# STM32F411VET6 register map
File version: 1.0
Registers are 32-bit, access not given, reset 0x0 unless marked. A register's access mark holds for its fields unless they carry their own. Offsets are from the block's base; [hi:lo] are bit positions; {n}, {i} and the like mark numbered series.

## FLASH
Base 0x40023C00
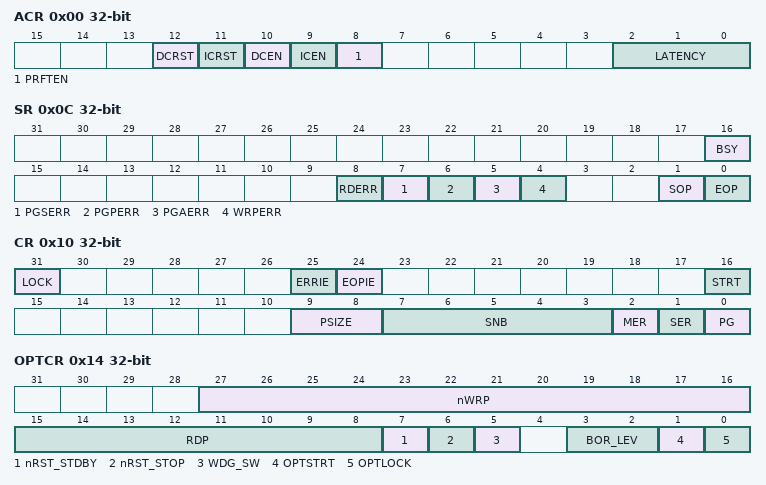
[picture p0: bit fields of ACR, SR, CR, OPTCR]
0x00 ACR
  [12] DCRST, [11] ICRST, [10] DCEN, [9] ICEN, [8] PRFTEN, [2:0] LATENCY
0x04 KEYR
0x08 OPTKEYR
0x0C SR
  [16] BSY, [8] RDERR, [7] PGSERR, [6] PGPERR, [5] PGAERR, [4] WRPERR, [1] SOP, [0] EOP
0x10 CR
  [31] LOCK, [25] ERRIE, [24] EOPIE, [16] STRT, [9:8] PSIZE, [7:3] SNB, [2] MER, [1] SER, [0] PG
0x14 OPTCR
  [27:16] nWRP, [15:8] RDP, [7] nRST_STDBY, [6] nRST_STOP, [5] WDG_SW, [3:2] BOR_LEV, [1] OPTSTRT, [0] OPTLOCK
0x18 OPTCR1
  [27:16] nWRP

## DMA1
Base 0x40026000
Same registers: DMA2 0x40026400
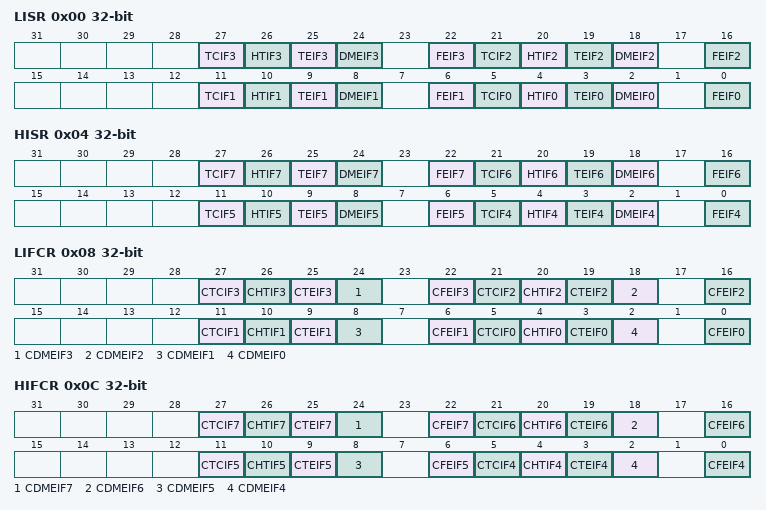
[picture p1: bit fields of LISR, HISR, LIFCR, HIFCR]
0x00 LISR
  [27] TCIF3, [26] HTIF3, [25] TEIF3, [24] DMEIF3, [22] FEIF3, [21] TCIF2, [20] HTIF2, [19] TEIF2, [18] DMEIF2, [16] FEIF2, [11] TCIF1, [10] HTIF1, [9] TEIF1, [8] DMEIF1, [6] FEIF1, [5] TCIF0, [4] HTIF0, [3] TEIF0, [2] DMEIF0, [0] FEIF0
0x04 HISR
  [27] TCIF7, [26] HTIF7, [25] TEIF7, [24] DMEIF7, [22] FEIF7, [21] TCIF6, [20] HTIF6, [19] TEIF6, [18] DMEIF6, [16] FEIF6, [11] TCIF5, [10] HTIF5, [9] TEIF5, [8] DMEIF5, [6] FEIF5, [5] TCIF4, [4] HTIF4, [3] TEIF4, [2] DMEIF4, [0] FEIF4
0x08 LIFCR
  [27] CTCIF3, [26] CHTIF3, [25] CTEIF3, [24] CDMEIF3, [22] CFEIF3, [21] CTCIF2, [20] CHTIF2, [19] CTEIF2, [18] CDMEIF2, [16] CFEIF2, [11] CTCIF1, [10] CHTIF1, [9] CTEIF1, [8] CDMEIF1, [6] CFEIF1, [5] CTCIF0, [4] CHTIF0, [3] CTEIF0, [2] CDMEIF0, [0] CFEIF0
0x0C HIFCR
  [27] CTCIF7, [26] CHTIF7, [25] CTEIF7, [24] CDMEIF7, [22] CFEIF7, [21] CTCIF6, [20] CHTIF6, [19] CTEIF6, [18] CDMEIF6, [16] CFEIF6, [11] CTCIF5, [10] CHTIF5, [9] CTEIF5, [8] CDMEIF5, [6] CFEIF5, [5] CTCIF4, [4] CHTIF4, [3] CTEIF4, [2] CDMEIF4, [0] CFEIF4
{0x10+0x18*i} CR{i} (i=0..7)
{0x14+0x18*i} NDTR{i} (i=0..7)
{0x18+0x18*i} PAR{i} (i=0..7)
{0x1C+0x18*i} M0AR{i} (i=0..7)
{0x20+0x18*i} M1AR{i} (i=0..7)
{0x24+0x18*i} FCR{i} (i=0..7)

## USB_OTG_FS
Base 0x50000000
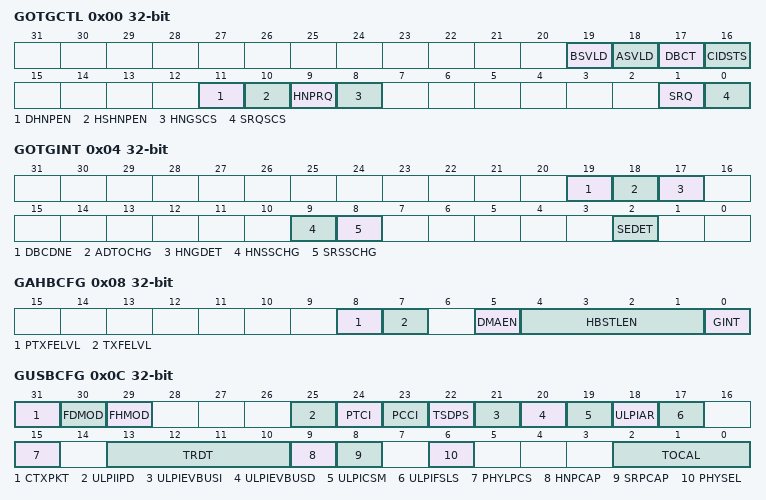
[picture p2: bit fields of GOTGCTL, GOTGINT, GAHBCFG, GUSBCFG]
0x00 GOTGCTL
  [19] BSVLD, [18] ASVLD, [17] DBCT, [16] CIDSTS, [11] DHNPEN, [10] HSHNPEN, [9] HNPRQ, [8] HNGSCS, [1] SRQ, [0] SRQSCS
0x04 GOTGINT
  [19] DBCDNE, [18] ADTOCHG, [17] HNGDET, [9] HNSSCHG, [8] SRSSCHG, [2] SEDET
0x08 GAHBCFG
  [8] PTXFELVL, [7] TXFELVL, [5] DMAEN, [4:1] HBSTLEN, [0] GINT
0x0C GUSBCFG
  [31] CTXPKT, [30] FDMOD, [29] FHMOD, [25] ULPIIPD, [24] PTCI, [23] PCCI, [22] TSDPS, [21] ULPIEVBUSI, [20] ULPIEVBUSD, [19] ULPICSM, [18] ULPIAR, [17] ULPIFSLS, [15] PHYLPCS, [13:10] TRDT, [9] HNPCAP, [8] SRPCAP, [6] PHYSEL, [2:0] TOCAL
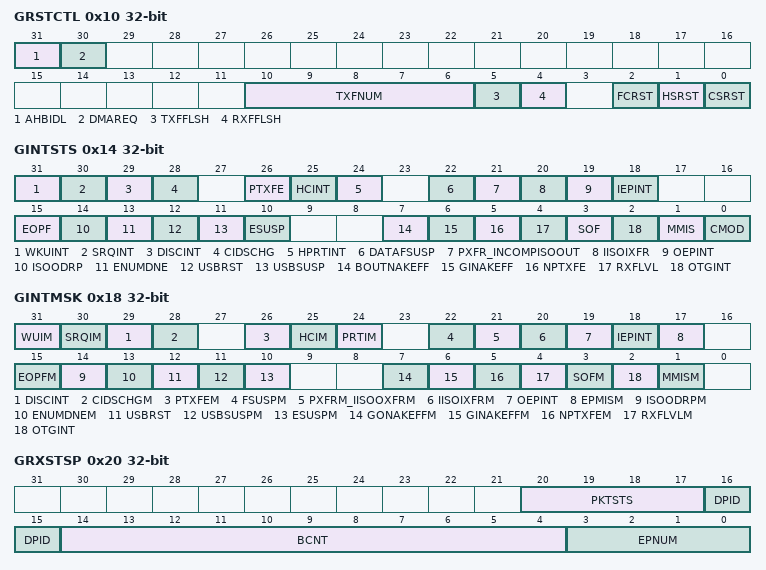
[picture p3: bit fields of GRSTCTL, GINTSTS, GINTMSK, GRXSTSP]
0x10 GRSTCTL
  [31] AHBIDL, [30] DMAREQ, [10:6] TXFNUM, [5] TXFFLSH, [4] RXFFLSH, [2] FCRST, [1] HSRST, [0] CSRST
0x14 GINTSTS
  [31] WKUINT, [30] SRQINT, [29] DISCINT, [28] CIDSCHG, [26] PTXFE, [25] HCINT, [24] HPRTINT, [22] DATAFSUSP, [21] PXFR_INCOMPISOOUT, [20] IISOIXFR, [19] OEPINT, [18] IEPINT, [15] EOPF, [14] ISOODRP, [13] ENUMDNE, [12] USBRST, [11] USBSUSP, [10] ESUSP, [7] BOUTNAKEFF, [6] GINAKEFF, [5] NPTXFE, [4] RXFLVL, [3] SOF, [2] OTGINT, [1] MMIS, [0] CMOD
0x18 GINTMSK
  [31] WUIM, [30] SRQIM, [29] DISCINT, [28] CIDSCHGM, [26] PTXFEM, [25] HCIM, [24] PRTIM, [22] FSUSPM, [21] PXFRM_IISOOXFRM, [20] IISOIXFRM, [19] OEPINT, [18] IEPINT, [17] EPMISM, [15] EOPFM, [14] ISOODRPM, [13] ENUMDNEM, [12] USBRST, [11] USBSUSPM, [10] ESUSPM, [7] GONAKEFFM, [6] GINAKEFFM, [5] NPTXFEM, [4] RXFLVLM, [3] SOFM, [2] OTGINT, [1] MMISM
0x1C GRXSTSR
0x20 GRXSTSP
  [20:17] PKTSTS, [16:15] DPID, [14:4] BCNT, [3:0] EPNUM
0x24 GRXFSIZ
  [15:0] RXFD
0x28 DIEPTXF0_HNPTXFSIZ
0x2C HNPTXSTS
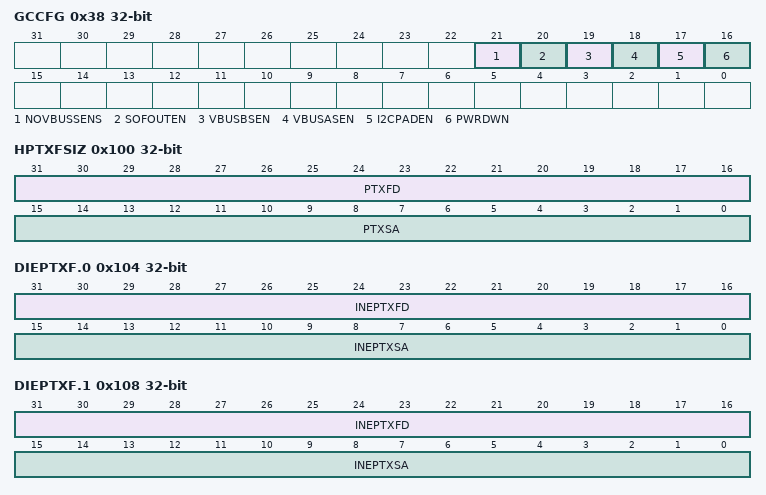
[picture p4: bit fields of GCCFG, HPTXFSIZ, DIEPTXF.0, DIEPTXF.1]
0x38 GCCFG
  [21] NOVBUSSENS, [20] SOFOUTEN, [19] VBUSBSEN, [18] VBUSASEN, [17] I2CPADEN, [16] PWRDWN
0x3C CID
  [31:0] PRODUCT_ID
0x100 HPTXFSIZ
  [31:16] PTXFD, [15:0] PTXSA
0x104 DIEPTXF.0
  [31:16] INEPTXFD, [15:0] INEPTXSA
0x108 DIEPTXF.1
  [31:16] INEPTXFD, [15:0] INEPTXSA
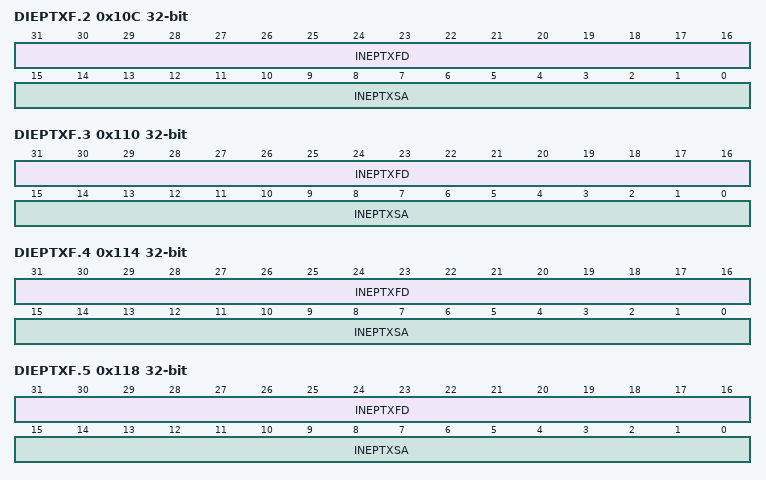
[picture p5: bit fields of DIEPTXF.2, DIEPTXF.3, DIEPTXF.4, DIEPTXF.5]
0x10C DIEPTXF.2
  [31:16] INEPTXFD, [15:0] INEPTXSA
0x110 DIEPTXF.3
  [31:16] INEPTXFD, [15:0] INEPTXSA
0x114 DIEPTXF.4
  [31:16] INEPTXFD, [15:0] INEPTXSA
0x118 DIEPTXF.5
  [31:16] INEPTXFD, [15:0] INEPTXSA
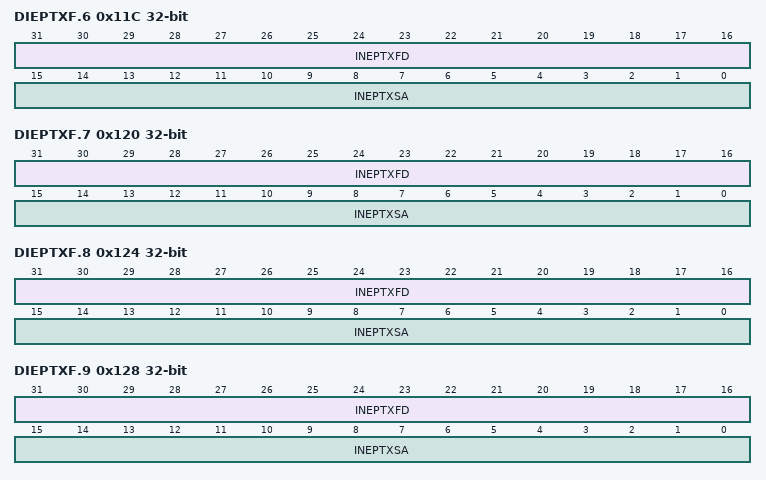
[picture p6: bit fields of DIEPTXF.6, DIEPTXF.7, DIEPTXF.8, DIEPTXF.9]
0x11C DIEPTXF.6
  [31:16] INEPTXFD, [15:0] INEPTXSA
0x120 DIEPTXF.7
  [31:16] INEPTXFD, [15:0] INEPTXSA
0x124 DIEPTXF.8
  [31:16] INEPTXFD, [15:0] INEPTXSA
0x128 DIEPTXF.9
  [31:16] INEPTXFD, [15:0] INEPTXSA
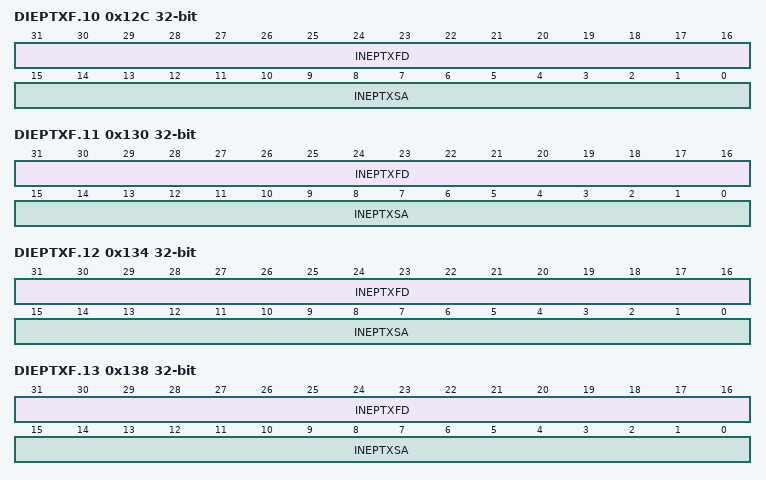
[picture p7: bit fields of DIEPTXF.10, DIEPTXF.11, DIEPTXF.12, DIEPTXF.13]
0x12C DIEPTXF.10
  [31:16] INEPTXFD, [15:0] INEPTXSA
0x130 DIEPTXF.11
  [31:16] INEPTXFD, [15:0] INEPTXSA
0x134 DIEPTXF.12
  [31:16] INEPTXFD, [15:0] INEPTXSA
0x138 DIEPTXF.13
  [31:16] INEPTXFD, [15:0] INEPTXSA
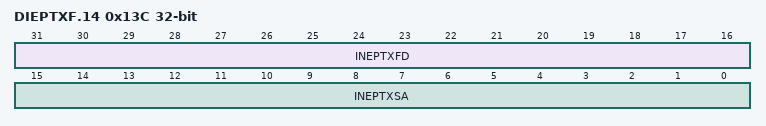
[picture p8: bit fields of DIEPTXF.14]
0x13C DIEPTXF.14
  [31:16] INEPTXFD, [15:0] INEPTXSA

## DBGMCU
Base 0xE0042000
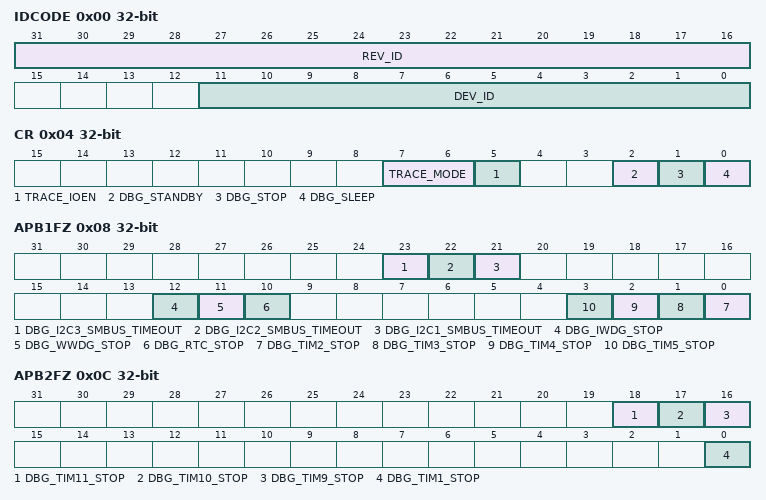
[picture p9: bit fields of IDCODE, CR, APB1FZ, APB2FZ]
0x00 IDCODE
  [31:16] REV_ID, [11:0] DEV_ID
0x04 CR
  [7:6] TRACE_MODE, [5] TRACE_IOEN, [2] DBG_STANDBY, [1] DBG_STOP, [0] DBG_SLEEP
0x08 APB1FZ
  [23] DBG_I2C3_SMBUS_TIMEOUT, [22] DBG_I2C2_SMBUS_TIMEOUT, [21] DBG_I2C1_SMBUS_TIMEOUT, [12] DBG_IWDG_STOP, [11] DBG_WWDG_STOP, [10] DBG_RTC_STOP, [n-2] DBG_TIM{n}_STOP (n=2..5)
0x0C APB2FZ
  [18] DBG_TIM11_STOP, [17] DBG_TIM10_STOP, [16] DBG_TIM9_STOP, [0] DBG_TIM1_STOP
